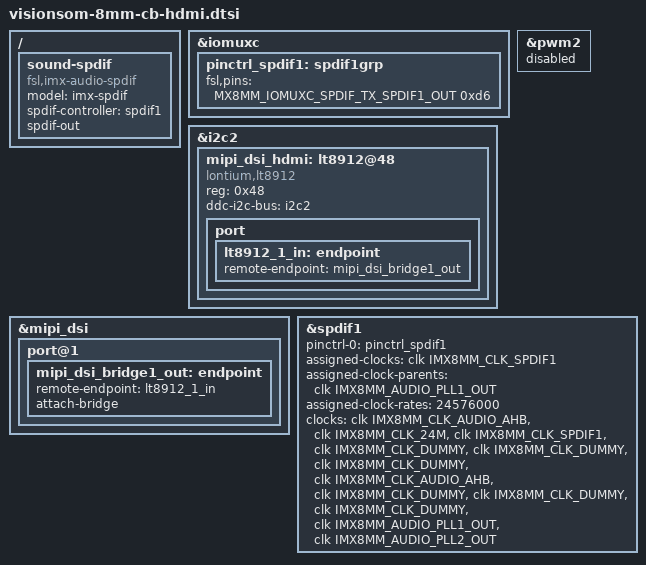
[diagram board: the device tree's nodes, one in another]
// SPDX-License-Identifier: GPL-2.0-or-later
/*
 * Copyright 2020 SomLabs
 *
 */

/ {
    /delete-node/ panel-backlight;

    sound-spdif {
        compatible = "fsl,imx-audio-spdif";
        model = "imx-spdif";
        spdif-controller = <&spdif1>;
        spdif-out;
    };
};


&iomuxc {
    pinctrl-names = "default";

    pinctrl_spdif1: spdif1grp {
        fsl,pins = <
            MX8MM_IOMUXC_SPDIF_TX_SPDIF1_OUT    0xd6
        >;
    };
};

&pwm2 {
    status = "disabled";
};

&i2c2 {
    /delete-node/ edt-ft5x06@38;

    /* MIPI-DSI to HDMI adapter */
    mipi_dsi_hdmi: lt8912@48 {
        compatible = "lontium,lt8912";
        reg = <0x48>;
        ddc-i2c-bus = <&i2c2>;
        status = "okay";

        port {
            lt8912_1_in: endpoint {
                remote-endpoint = <&mipi_dsi_bridge1_out>;
            };
        };
    };
};

&mipi_dsi {
    status = "okay";

    /delete-node/ panel@0;

    port@1 {
        mipi_dsi_bridge1_out: endpoint {
            remote-endpoint = <&lt8912_1_in>;
            attach-bridge;
        };
    };
};

&spdif1 {
    pinctrl-names = "default";
    pinctrl-0 = <&pinctrl_spdif1>;
    assigned-clocks = <&clk IMX8MM_CLK_SPDIF1>;
    assigned-clock-parents = <&clk IMX8MM_AUDIO_PLL1_OUT>;
    assigned-clock-rates = <24576000>;
    clocks = <&clk IMX8MM_CLK_AUDIO_AHB>, <&clk IMX8MM_CLK_24M>,
        <&clk IMX8MM_CLK_SPDIF1>, <&clk IMX8MM_CLK_DUMMY>,
        <&clk IMX8MM_CLK_DUMMY>, <&clk IMX8MM_CLK_DUMMY>,
        <&clk IMX8MM_CLK_AUDIO_AHB>, <&clk IMX8MM_CLK_DUMMY>,
        <&clk IMX8MM_CLK_DUMMY>, <&clk IMX8MM_CLK_DUMMY>,
        <&clk IMX8MM_AUDIO_PLL1_OUT>, <&clk IMX8MM_AUDIO_PLL2_OUT>;
    clock-names = "core", "rxtx0", "rxtx1", "rxtx2", "rxtx3",
        "rxtx4", "rxtx5", "rxtx6", "rxtx7", "spba", "pll8k", "pll11k";
    status = "okay";
};
